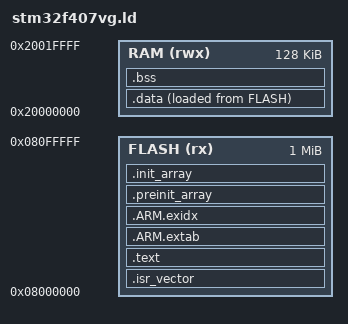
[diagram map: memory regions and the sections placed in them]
/* Memory map of the STM32F407VG: 1 MB flash, 128 KB main RAM.
 * Like ../capture/stm32f407vg.ld, plus what C++ and the C library need:
 * constructor lists (ExecuTorch registers its kernels from constructors),
 * unwind tables, and a heap between the end of .bss and the stack. */
ENTRY(Reset_Handler)

MEMORY
{
    FLASH (rx)  : ORIGIN = 0x08000000, LENGTH = 1024K
    RAM   (rwx) : ORIGIN = 0x20000000, LENGTH = 128K
}

_estack = ORIGIN(RAM) + LENGTH(RAM);   /* stack starts at the top of RAM */
_stack_size = 16K;                     /* kept free for the stack (checked below) */

SECTIONS
{
    .isr_vector : { KEEP(*(.isr_vector)) } > FLASH

    .text : {
        *(.text*)
        *(.rodata*)
        KEEP(*(.init))
        KEEP(*(.fini))
        . = ALIGN(4);
    } > FLASH

    .ARM.extab : { *(.ARM.extab* .gnu.linkonce.armextab.*) } > FLASH
    .ARM.exidx : { *(.ARM.exidx* .gnu.linkonce.armexidx.*) } > FLASH

    .preinit_array : {
        PROVIDE_HIDDEN(__preinit_array_start = .);
        KEEP(*(.preinit_array*))
        PROVIDE_HIDDEN(__preinit_array_end = .);
    } > FLASH
    .init_array : {
        PROVIDE_HIDDEN(__init_array_start = .);
        KEEP(*(SORT(.init_array.*)))
        KEEP(*(.init_array*))
        PROVIDE_HIDDEN(__init_array_end = .);
    } > FLASH

    _sidata = LOADADDR(.data);
    .data : {
        . = ALIGN(4);
        _sdata = .;
        *(.data*)
        . = ALIGN(4);
        _edata = .;
    } > RAM AT > FLASH

    .bss (NOLOAD) : {
        . = ALIGN(4);
        _sbss = .;
        *(.bss*)
        *(COMMON)
        . = ALIGN(8);
        _ebss = .;
    } > RAM

    _heap_start = _ebss;
    _heap_end = _estack - _stack_size;
    ASSERT(_heap_end >= _heap_start, "not enough RAM left for the 16 KB stack")
}
